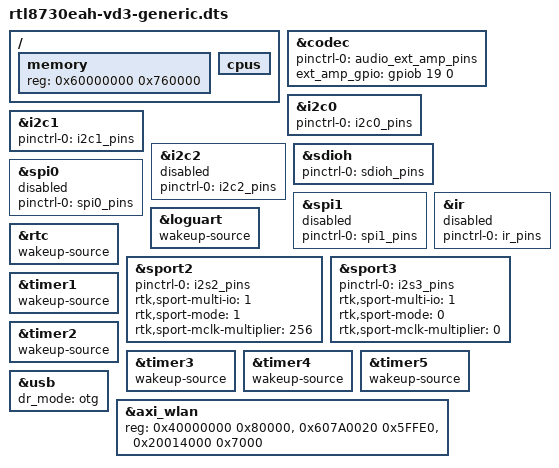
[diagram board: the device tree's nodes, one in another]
// SPDX-License-Identifier: GPL-2.0-only
/*
* Realtek generic DTS
*
* Copyright (C) 2023, Realtek Corporation. All rights reserved.
*/

/dts-v1/;

#include "rtl8730e.dtsi"
#include "rtl8730e-spi-nor-xip.dtsi"

/ {
	memory {
		device_type = "memory";
		// Base 0x60000000 (2MB-aligned; ARM nomaps unaligned head) = CONFIG_PHYS_OFFSET / U-Boot TEXT_BASE.
		// 7552K: SEC_DRAM slimmed to 256K at PSRAM top; see firmware ameba_layout.ld.
        reg = <0x60000000 0x760000>;
	};

	cpus {
		// This board runs a single-core kernel (CONFIG_SMP off for XIP), so drop
		// cpu@1 from the shared a32.dtsi -- devtree.c warns and caps otherwise.
		/delete-node/ cpu@1;
	};
};

// Configure pinmux, avoid the pin conflict.

&codec{
	pinctrl-names = "default";
	pinctrl-0 = <&audio_ext_amp_pins>;
	ext_amp_gpio = <&gpiob 19 0>;
};

&i2c0{
	pinctrl-names = "default";
	pinctrl-0 = <&i2c0_pins>;
	status = "okay";
};

&i2c1{
	pinctrl-names = "default";
	pinctrl-0 = <&i2c1_pins>;
	status = "okay";
};

&i2c2{
	pinctrl-names = "default";
	pinctrl-0 = <&i2c2_pins>;
	status = "disabled";
};

&sdioh {
	pinctrl-names = "default";
	pinctrl-0 = <&sdioh_pins>;
	status = "okay";
};

&spi0{
	pinctrl-names = "default";
	pinctrl-0 = <&spi0_pins>;
	status = "disabled";
};

&spi1{
	pinctrl-names = "default";
	pinctrl-0 = <&spi1_pins>;
	status = "disabled";
};

&ir{
	pinctrl-names = "default";
	pinctrl-0 = <&ir_pins>;
	status = "disabled";
};

&loguart{
	wakeup-source;
};

&rtc{
	wakeup-source;
};

&sport2 {
	pinctrl-names = "default";
	pinctrl-0 = <&i2s2_pins>;
	rtk,sport-multi-io = <1>;
	rtk,sport-mode = <1>;
	rtk,sport-mclk-multiplier = <256>;
};

&sport3 {
	pinctrl-names = "default";
	pinctrl-0 = <&i2s3_pins>;
	rtk,sport-multi-io = <1>;
	rtk,sport-mode = <0>;
	rtk,sport-mclk-multiplier = <0>;
};

&timer1{
	wakeup-source;
};

&timer2{
	wakeup-source;
};

&timer3{
	wakeup-source;
};

&timer4{
	wakeup-source;
};

&timer5{
	wakeup-source;
};

&usb {
	dr_mode = "otg"; // "host", "peripheral", "otg"
};

&axi_wlan {
	/* Override rtl8730e-ocp.dtsi: under CONFIG_IMG2_FLASH, KM4_BD_DRAM is at PSRAM top (0x607A0020,384K)
	 * and KM4 keeps runtime data in SRAM (0x20014000,28K) -- both windows must be mapped for the WiFi host driver. */
	reg = <0x40000000 0x80000>,	// wifi register base address and length
		<0x607A0020 0x5FFE0>,	// KM4_BD_DRAM (CONFIG_IMG2_FLASH, top of PSRAM)
		<0x20014000 0x7000>;	// KM4_BD_RAM SRAM (KM4 flash-XIP runtime data)
};
